VERSION ""

NS_ :

BS_:

BU_: XXX INTERCEPTOR EON HCU

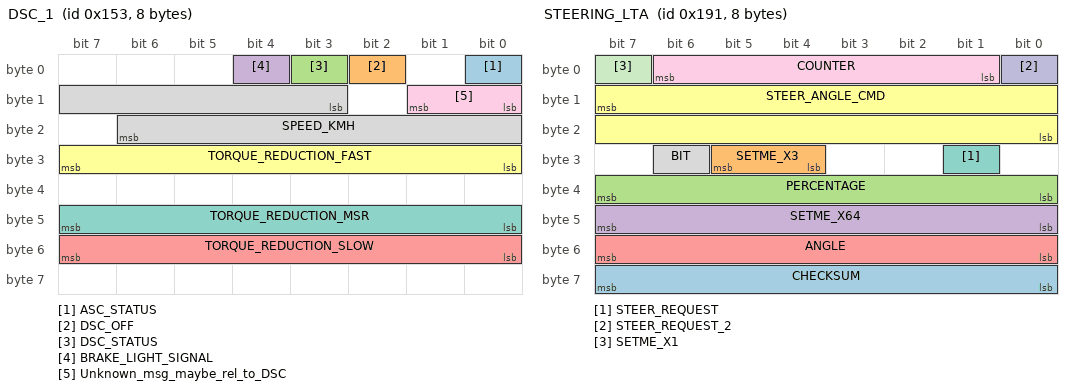
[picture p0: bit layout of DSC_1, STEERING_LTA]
BO_ 339 DSC_1: 8 XXX
 SG_ ASC_STATUS : 0|1@1+ (1,0) [0|3] "" XXX
 SG_ DSC_OFF : 2|1@1+ (1,0) [0|3] "" XXX
 SG_ DSC_STATUS : 3|1@0+ (1,0) [0|3] "" XXX
 SG_ BRAKE_LIGHT_SIGNAL : 4|1@0+ (1,0) [0|3] "" XXX
 SG_ TORQUE_REDUCTION_SLOW : 55|8@0+ (1,0) [0|255] "" XXX
 SG_ TORQUE_REDUCTION_FAST : 31|8@0+ (1,0) [0|255] "" XXX
 SG_ TORQUE_REDUCTION_MSR : 47|8@0+ (1,0) [0|255] "" XXX
 SG_ SPEED_KMH : 11|12@1+ (0.0625,-2.64) [0|1] "kmh" XXX
 SG_ Unknown_msg_maybe_rel_to_DSC : 8|2@1+ (1,0) [0|3] "" XXX

BO_ 401 STEERING_LTA: 8 XXX
 SG_ CHECKSUM : 63|8@0+ (1,0) [0|255] "" XXX
 SG_ SETME_X3 : 29|2@0+ (1,0) [0|3] "" XXX
 SG_ PERCENTAGE : 39|8@0+ (1,0) [0|255] "" XXX
 SG_ SETME_X64 : 47|8@0+ (1,0) [0|255] "" XXX
 SG_ ANGLE : 55|8@0- (0.5,0) [0|255] "" XXX
 SG_ STEER_ANGLE_CMD : 15|16@0- (0.0573,0) [-540|540] "" XXX
 SG_ STEER_REQUEST : 25|1@0+ (1,0) [0|1] "" XXX
 SG_ BIT : 30|1@0+ (1,0) [0|1] "" XXX
 SG_ COUNTER : 6|6@0+ (1,0) [0|255] "" XXX
 SG_ STEER_REQUEST_2 : 0|1@0+ (1,0) [0|1] "" XXX
 SG_ SETME_X1 : 7|1@0+ (1,0) [0|1] "" XXX

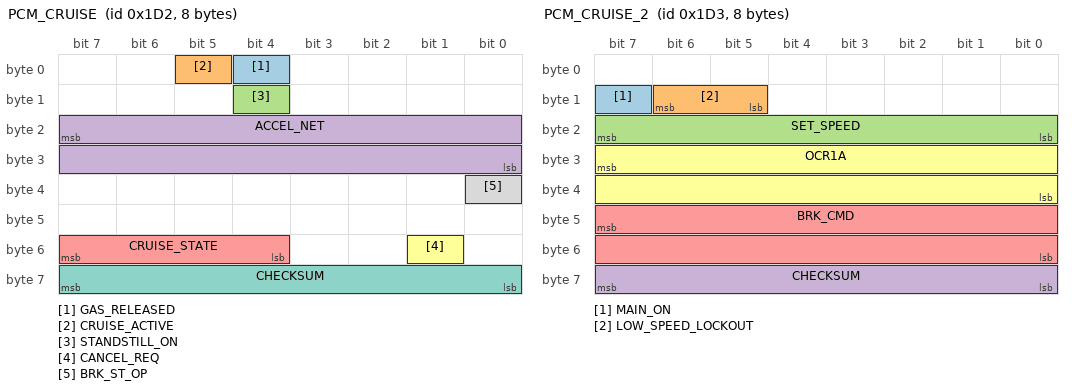
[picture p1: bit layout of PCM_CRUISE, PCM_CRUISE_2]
BO_ 466 PCM_CRUISE: 8 XXX
 SG_ GAS_RELEASED : 4|1@0+ (1,0) [0|1] "" XXX
 SG_ CRUISE_ACTIVE : 5|1@0+ (1,0) [0|1] "" XXX
 SG_ STANDSTILL_ON : 12|1@0+ (1,0) [0|1] "" XXX
 SG_ ACCEL_NET : 23|16@0- (0.001,0) [-20|20] "m/s2" XXX
 SG_ CRUISE_STATE : 55|4@0+ (1,0) [0|15] "" XXX
 SG_ CANCEL_REQ : 49|1@1+ (1,0) [0|1] "" XXX
 SG_ CHECKSUM : 63|8@0+ (1,0) [0|255] "" XXX
 SG_ BRK_ST_OP : 32|1@1+ (1,0) [0|3] "" XXX

BO_ 467 PCM_CRUISE_2: 8 XXX
 SG_ MAIN_ON : 15|1@0+ (1,0) [0|1] "" XXX
 SG_ LOW_SPEED_LOCKOUT : 14|2@0+ (1,0) [0|3] "kph" XXX
 SG_ SET_SPEED : 23|8@0+ (1,0) [0|255] "kph" XXX
 SG_ CHECKSUM : 63|8@0+ (1,0) [0|255] "" XXX
 SG_ BRK_CMD : 47|16@0- (1,0) [0|65535] "" XXX
 SG_ OCR1A : 31|16@0+ (1,0) [0|65535] "" XXX

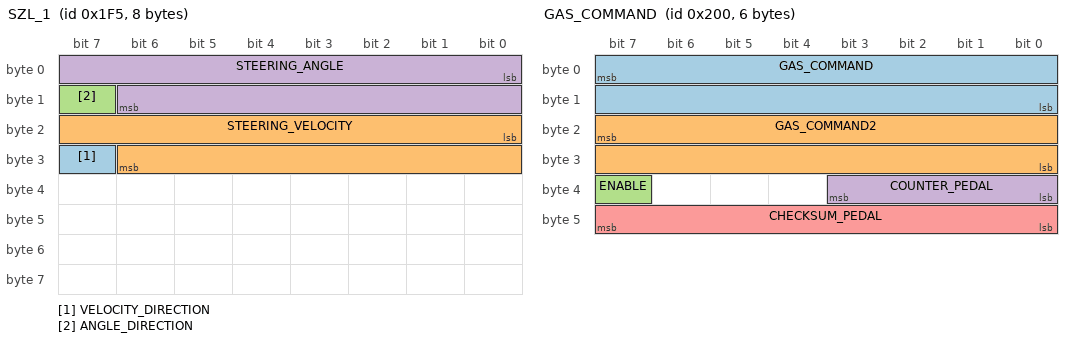
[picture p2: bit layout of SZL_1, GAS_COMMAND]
BO_ 501 SZL_1: 8 XXX
 SG_ VELOCITY_DIRECTION : 31|1@0+ (1,0) [0|1] "" XXX
 SG_ STEERING_VELOCITY : 16|15@1+ (0.045,0) [0|1] "deg/s" XXX
 SG_ ANGLE_DIRECTION : 15|1@0+ (1,0) [0|1] "" XXX
 SG_ STEERING_ANGLE : 0|15@1+ (0.045,0) [0|1] "deg" XXX

BO_ 512 GAS_COMMAND: 6 EON
 SG_ GAS_COMMAND : 7|16@0+ (0.159375,-75.555) [0|1] "" INTERCEPTOR
 SG_ GAS_COMMAND2 : 23|16@0+ (0.159375,-151.111) [0|1] "" INTERCEPTOR
 SG_ ENABLE : 39|1@0+ (1,0) [0|1] "" INTERCEPTOR
 SG_ COUNTER_PEDAL : 35|4@0+ (1,0) [0|15] "" INTERCEPTOR
 SG_ CHECKSUM_PEDAL : 47|8@0+ (1,0) [0|255] "" INTERCEPTOR

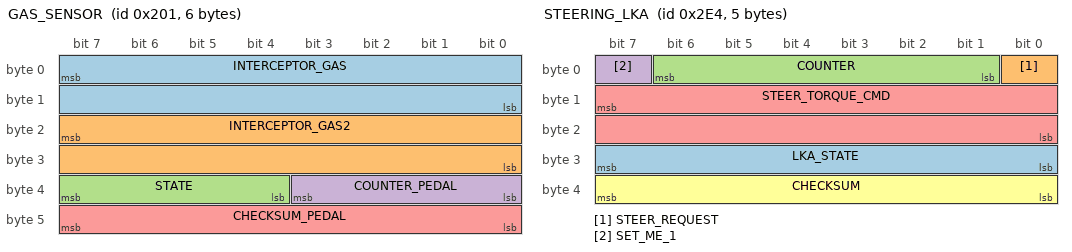
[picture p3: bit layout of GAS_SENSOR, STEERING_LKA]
BO_ 513 GAS_SENSOR: 6 INTERCEPTOR
 SG_ INTERCEPTOR_GAS : 7|16@0+ (0.159375,-75.555) [0|1] "" EON
 SG_ INTERCEPTOR_GAS2 : 23|16@0+ (0.159375,-151.111) [0|1] "" EON
 SG_ STATE : 39|4@0+ (1,0) [0|15] "" EON
 SG_ COUNTER_PEDAL : 35|4@0+ (1,0) [0|15] "" EON
 SG_ CHECKSUM_PEDAL : 47|8@0+ (1,0) [0|255] "" EON

BO_ 740 STEERING_LKA: 5 XXX
 SG_ LKA_STATE : 31|8@0+ (1,0) [0|255] "" XXX
 SG_ STEER_REQUEST : 0|1@0+ (1,0) [0|1] "" XXX
 SG_ COUNTER : 6|6@0+ (1,0) [0|63] "" XXX
 SG_ SET_ME_1 : 7|1@0+ (1,0) [0|1] "" XXX
 SG_ STEER_TORQUE_CMD : 15|16@0- (1,0) [0|65535] "" XXX
 SG_ CHECKSUM : 39|8@0+ (1,0) [0|255] "" XXX

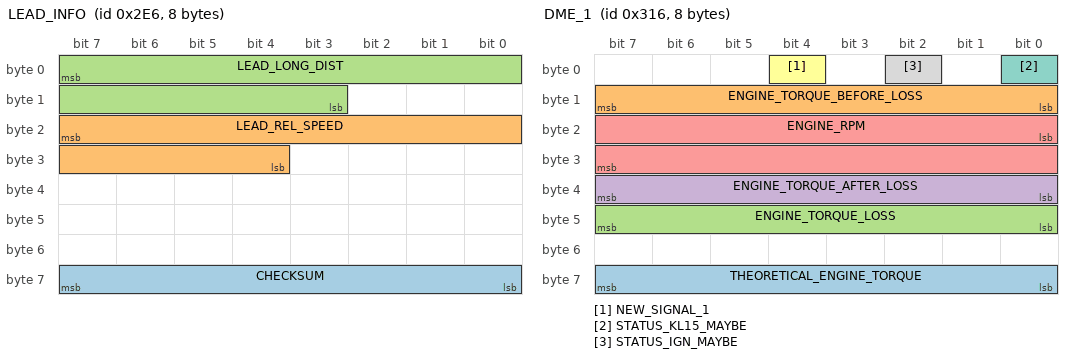
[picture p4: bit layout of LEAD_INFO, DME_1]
BO_ 742 LEAD_INFO: 8 DSU
 SG_ CHECKSUM : 63|8@0+ (1,0) [0|255] "" HCU
 SG_ LEAD_REL_SPEED : 23|12@0- (0.025,0) [-100|100] "m/s" HCU
 SG_ LEAD_LONG_DIST : 7|13@0+ (0.05,0) [0|300] "m" HCU

BO_ 790 DME_1: 8 XXX
 SG_ THEORETICAL_ENGINE_TORQUE : 63|8@0+ (1,0) [0|65535] "" XXX
 SG_ ENGINE_TORQUE_BEFORE_LOSS : 8|8@1+ (1,0) [0|65535] "" XXX
 SG_ ENGINE_TORQUE_LOSS : 47|8@0+ (1,0) [0|255] "" XXX
 SG_ ENGINE_TORQUE_AFTER_LOSS : 39|8@0+ (1,0) [0|65535] "" XXX
 SG_ ENGINE_RPM : 16|16@1+ (0.15625,0) [0|65535] "" XXX
 SG_ NEW_SIGNAL_1 : 4|1@0+ (1,0) [0|3] "" XXX
 SG_ STATUS_KL15_MAYBE : 0|1@0+ (1,0) [0|1] "" XXX
 SG_ STATUS_IGN_MAYBE : 2|1@0+ (1,0) [0|1] "" XXX

BO_ 809 DME_2: 8 XXX
 SG_ CRUISE_CONTROL_REQUESTED_LOAD : 39|8@0+ (1,0) [0|255] "" XXX
 SG_ CRUISE_CONTROL_ENABLED : 51|1@0+ (1,0) [0|1] "" XXX
 SG_ BRAKE_LIGHT_SIGNAL_ERROR : 49|1@0+ (1,0) [0|1] "" XXX
 SG_ BRAKE_LIGHT_SIGNAL : 48|1@0+ (1,0) [0|1] "" XXX
 SG_ ATMOSPHERIC_PRESSURE : 23|8@0+ (2,597) [0|255] "mbar" XXX
 SG_ MULTIPLEXD_MSG : 7|8@0+ (1,0) [0|255] "" XXX
 SG_ COOLANT_TEMP : 15|8@0+ (0.75,-48) [0|255] "" XXX
 SG_ CRUISE_I_O : 31|1@0+ (1,0) [0|1] "" XXX
 SG_ CRUISE_AC_DECELARATION : 53|2@0+ (1,0) [0|3] "" XXX
 SG_ NEW_SIGNAL : 25|1@1+ (1,0) [0|3] "" XXX
 SG_ KICK_DOWN : 50|1@0+ (1,0) [0|1] "" XXX
 SG_ GAS_PEDAL : 47|8@0+ (0.005,0) [0|1] "" XXX
 SG_ CRUISE_CONTROL_UP : 29|1@0+ (1,0) [0|1] "" XXX
 SG_ CRUISE_CONTROL_DOWN : 30|1@0+ (1,0) [0|1] "" XXX
 SG_ RESUME_BTN : 30|2@0+ (1,0) [0|3] "" XXX

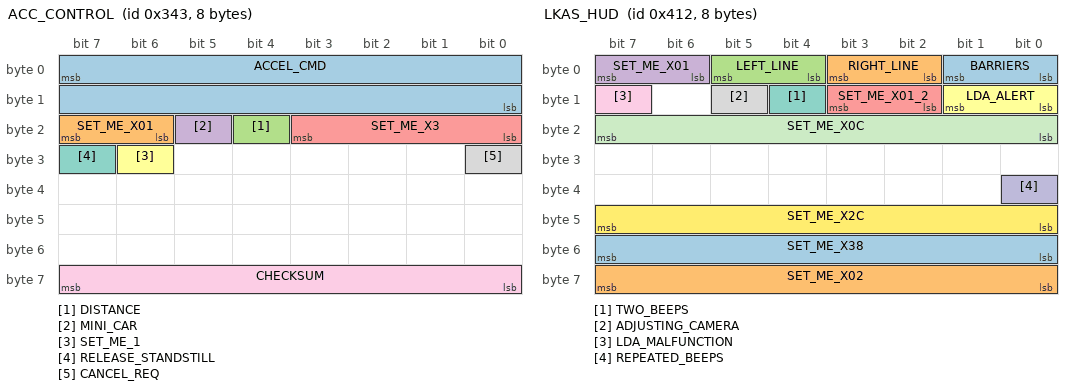
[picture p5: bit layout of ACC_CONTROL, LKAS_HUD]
BO_ 835 ACC_CONTROL: 8 DSU
 SG_ ACCEL_CMD : 7|16@0- (0.001,0) [-20|20] "m/s2" HCU
 SG_ SET_ME_X01 : 23|2@0+ (1,0) [0|3] "" HCU
 SG_ DISTANCE : 20|1@0+ (1,0) [0|1] "" XXX
 SG_ MINI_CAR : 21|1@0+ (1,0) [0|1] "" XXX
 SG_ SET_ME_X3 : 19|4@0+ (1,0) [0|15] "" XXX
 SG_ SET_ME_1 : 30|1@0+ (1,0) [0|1] "" HCU
 SG_ RELEASE_STANDSTILL : 31|1@0+ (1,0) [0|1] "" HCU
 SG_ CANCEL_REQ : 24|1@0+ (1,0) [0|1] "" HCU
 SG_ CHECKSUM : 63|8@0+ (1,0) [0|255] "" XXX

BO_ 1042 LKAS_HUD: 8 XXX
 SG_ BARRIERS : 1|2@0+ (1,0) [0|3] "" XXX
 SG_ RIGHT_LINE : 3|2@0+ (1,0) [0|3] "" XXX
 SG_ LEFT_LINE : 5|2@0+ (1,0) [0|3] "" XXX
 SG_ SET_ME_X01 : 7|2@0+ (1,0) [0|3] "" XXX
 SG_ SET_ME_X01_2 : 11|2@0+ (1,0) [0|3] "" XXX
 SG_ LDA_ALERT : 9|2@0+ (1,0) [0|3] "" XXX
 SG_ TWO_BEEPS : 12|1@0+ (1,0) [0|1] "" XXX
 SG_ ADJUSTING_CAMERA : 13|1@0+ (1,0) [0|1] "" XXX
 SG_ LDA_MALFUNCTION : 15|1@0+ (1,0) [0|1] "" XXX
 SG_ REPEATED_BEEPS : 32|1@0+ (1,0) [0|1] "" XXX
 SG_ SET_ME_X0C : 23|8@0+ (1,0) [0|1] "" XXX
 SG_ SET_ME_X2C : 47|8@0+ (1,0) [0|1] "" XXX
 SG_ SET_ME_X38 : 55|8@0+ (1,0) [0|1] "" XXX
 SG_ SET_ME_X02 : 63|8@0+ (1,0) [0|1] "" XXX

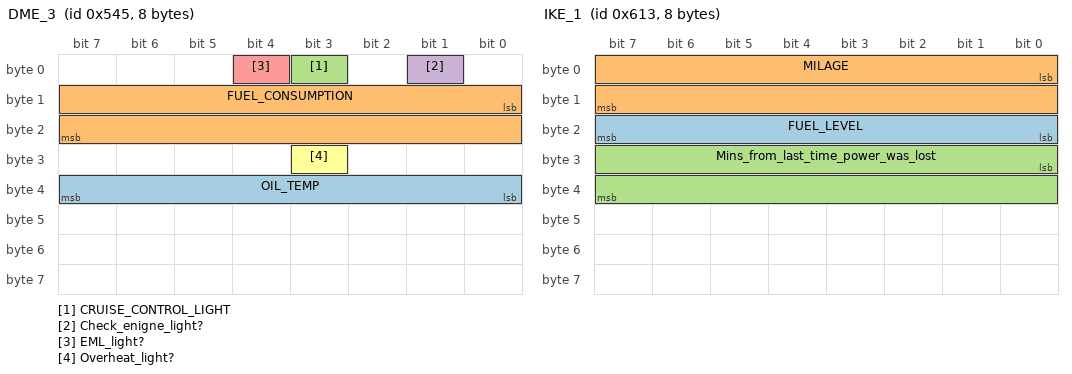
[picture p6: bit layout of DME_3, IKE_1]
BO_ 1349 DME_3: 8 XXX
 SG_ OIL_TEMP : 39|8@0+ (1,-48) [0|255] "" XXX
 SG_ FUEL_CONSUMPTION : 8|16@1+ (1,0) [0|255] "" XXX
 SG_ CRUISE_CONTROL_LIGHT : 3|1@0+ (1,0) [0|1] "" XXX
 SG_ Check_enigne_light? : 1|1@0+ (1,0) [0|1] "" XXX
 SG_ EML_light? : 4|1@0+ (1,0) [0|1] "" XXX
 SG_ Overheat_light? : 27|1@0+ (1,0) [0|3] "" XXX

BO_ 1555 IKE_1: 8 XXX
 SG_ FUEL_LEVEL : 23|8@0+ (1,0) [0|255] "" XXX
 SG_ MILAGE : 0|16@1+ (10,0) [0|65535] "" XXX
 SG_ Mins_from_last_time_power_was_lost : 24|16@1+ (1,0) [0|65535] "" XXX

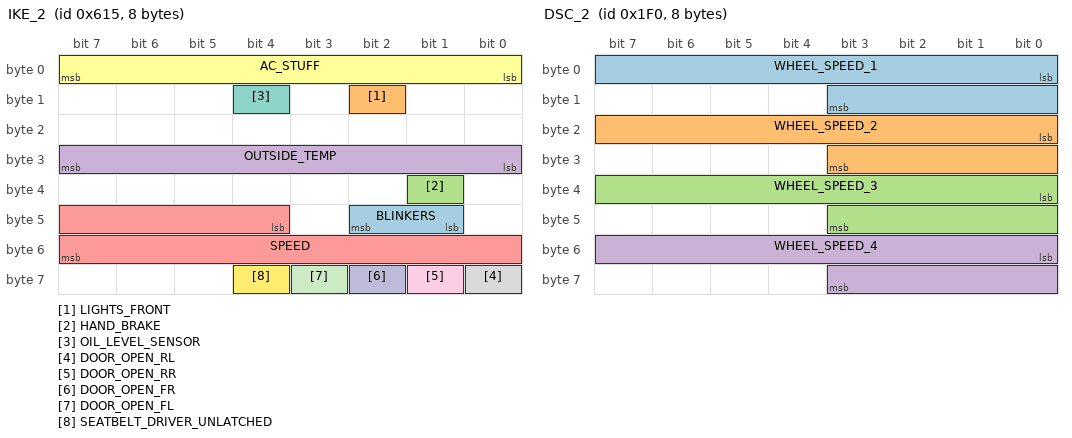
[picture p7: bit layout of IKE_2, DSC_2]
BO_ 1557 IKE_2: 8 XXX
 SG_ BLINKERS : 42|2@0+ (1,0) [0|3] "" XXX
 SG_ LIGHTS_FRONT : 10|1@1+ (1,0) [0|3] "" XXX
 SG_ HAND_BRAKE : 33|1@1+ (1,0) [0|3] "" XXX
 SG_ OUTSIDE_TEMP : 31|8@0+ (1,0) [0|255] "°C" XXX
 SG_ SPEED : 44|12@1+ (0.11,0) [0|4095] "kph" XXX
 SG_ AC_STUFF : 7|8@0+ (1,0) [0|31] "" XXX
 SG_ OIL_LEVEL_SENSOR : 12|1@0+ (1,0) [0|1] "" XXX
 SG_ DOOR_OPEN_RL : 56|1@0+ (1,0) [0|1] "" XXX
 SG_ DOOR_OPEN_RR : 57|1@0+ (1,0) [0|1] "" XXX
 SG_ DOOR_OPEN_FR : 58|1@0+ (1,0) [0|1] "" XXX
 SG_ DOOR_OPEN_FL : 59|1@0+ (1,0) [0|1] "" XXX
 SG_ SEATBELT_DRIVER_UNLATCHED : 60|1@0+ (1,0) [0|1] "" XXX

BO_ 496 DSC_2: 8 XXX
 SG_ WHEEL_SPEED_1 : 0|12@1+ (0.0625,-2.64) [0|4095] "km/h" XXX
 SG_ WHEEL_SPEED_2 : 16|12@1+ (0.0625,-2.64) [0|4095] "km/h" XXX
 SG_ WHEEL_SPEED_3 : 32|12@1+ (0.0625,-2.64) [0|4095] "km/h" XXX
 SG_ WHEEL_SPEED_4 : 48|12@1+ (0.0625,-2.64) [0|4095] "km/h" XXX

BO_ 499 DSC_3: 8 XXX
 SG_ LATERAL_ACCELERATION : 0|16@1- (1,0) [0|65535] "" XXX
 SG_ LONGITUDINAL_ACCELERATION : 16|16@1- (1,0) [0|65535] "" XXX

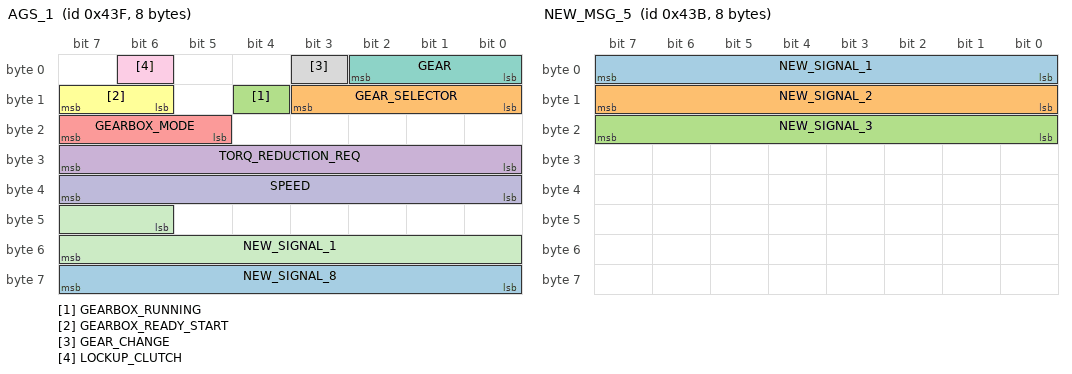
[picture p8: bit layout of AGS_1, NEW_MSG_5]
BO_ 1087 AGS_1: 8 XXX
 SG_ NEW_SIGNAL_8 : 63|8@0+ (1,0) [0|1] "" XXX
 SG_ GEAR_SELECTOR : 11|4@0+ (1,0) [0|1] "" XXX
 SG_ GEARBOX_RUNNING : 12|1@0+ (1,0) [0|3] "" XXX
 SG_ TORQ_REDUCTION_REQ : 31|8@0+ (1,0) [0|255] "" XXX
 SG_ GEARBOX_MODE : 23|3@0+ (1,0) [0|1] "" XXX
 SG_ GEARBOX_READY_START : 15|2@0+ (1,0) [0|1] "" XXX
 SG_ GEAR : 0|3@1+ (1,0) [0|7] "" XXX
 SG_ GEAR_CHANGE : 3|1@1+ (1,0) [0|7] "" XXX
 SG_ LOCKUP_CLUTCH : 6|1@0+ (1,0) [0|3] "" XXX
 SG_ SPEED : 39|8@0+ (1.37,0) [0|1] "" XXX
 SG_ NEW_SIGNAL_1 : 46|10@1+ (1,0) [0|255] "" XXX

BO_ 1916 NEW_MSG_2: 8 XXX
 SG_ ACCELEROMETER : 16|16@1- (1,0) [0|1] "" XXX

BO_ 1919 NEW_MSG_3: 8 XXX
 SG_ BRAKE_PRESSURE : 48|16@1+ (0.025,0) [0|65535] "" XXX

BO_ 1973 NEW_MSG_4: 8 XXX

BO_ 1083 NEW_MSG_5: 8 XXX
 SG_ NEW_SIGNAL_1 : 7|8@0+ (1,0) [0|1] "" XXX
 SG_ NEW_SIGNAL_2 : 15|8@0+ (1,0) [0|1] "" XXX
 SG_ NEW_SIGNAL_3 : 23|8@0+ (1,0) [0|1] "" XXX

CM_ SG_ 501 VELOCITY_DIRECTION "0 is left and 1 is right";
CM_ SG_ 501 ANGLE_DIRECTION "0 is left and 1 is right";
CM_ SG_ 809 RESUME_BTN "1 is UP 2 is DOWN and 3 is RESUME";
CM_ SG_ 1349 Check_enigne_light? "Goes to zero right afer startup";
CM_ SG_ 1349 EML_light? "Goes to zero right after ignition activation";
CM_ SG_ 1555 FUEL_LEVEL "In liters";
CM_ SG_ 496 WHEEL_SPEED_1 "raw wheel speed";
CM_ SG_ 496 WHEEL_SPEED_2 "raw wheel speed";
CM_ SG_ 496 WHEEL_SPEED_3 "raw wheel speed";
CM_ SG_ 496 WHEEL_SPEED_4 "raw wheel speed";
VAL_ 513 STATE 5 "FAULT_TIMEOUT" 4 "FAULT_STARTUP" 3 "FAULT_SCE" 2 "FAULT_SEND" 1 "FAULT_BAD_CHECKSUM" 0 "NO_FAULT" ;
